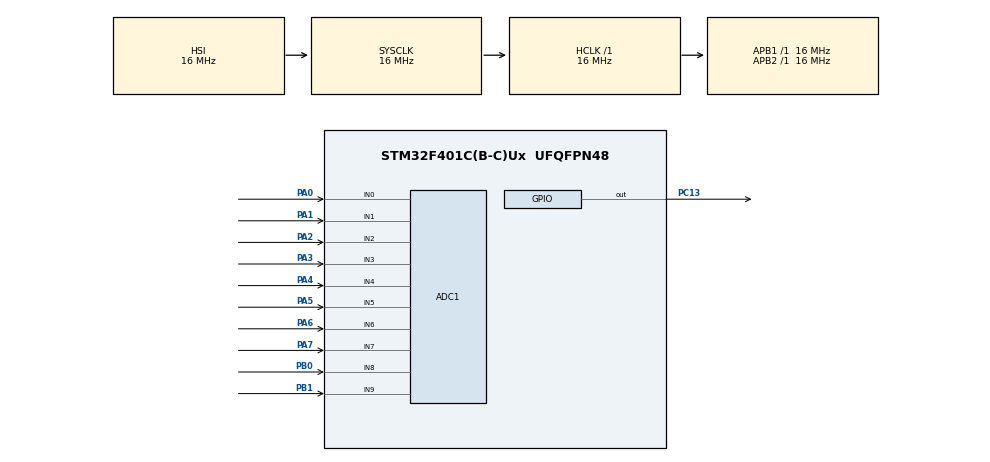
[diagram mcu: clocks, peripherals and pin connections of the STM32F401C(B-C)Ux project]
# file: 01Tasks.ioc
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ADC1.Channel-0\#ChannelRegularConversion=ADC_CHANNEL_0
ADC1.NbrOfConversionFlag=1
ADC1.Rank-0\#ChannelRegularConversion=1
ADC1.SamplingTime-0\#ChannelRegularConversion=ADC_SAMPLETIME_3CYCLES
ADC1.master=1
Mcu.Family=STM32F4
Mcu.Name=STM32F401C(B-C)Ux
Mcu.Package=UFQFPN48
NVIC.PriorityGroup=NVIC_PRIORITYGROUP_4
NVIC.TIM5_IRQn=true\:15\:0\:false\:false\:true\:false\:true\:true
NVIC.TimeBase=TIM5_IRQn
NVIC.TimeBaseIP=TIM5
PA0-WKUP.Signal=ADCx_IN0
PA1.Signal=ADCx_IN1
PA2.Signal=ADCx_IN2
PA3.Signal=ADCx_IN3
PA4.Signal=ADCx_IN4
PA5.Signal=ADCx_IN5
PA6.Signal=ADCx_IN6
PA7.Signal=ADCx_IN7
PB0.Signal=ADCx_IN8
PB1.Signal=ADCx_IN9
PC13-ANTI_TAMP.Signal=GPIO_Output
ProjectManager.HeapSize=0x100
ProjectManager.StackSize=0x200
ProjectManager.TargetToolchain=STM32CubeIDE
RCC.AHBFreq_Value=16000000
RCC.APB1Freq_Value=16000000
RCC.APB1TimFreq_Value=16000000
RCC.APB2Freq_Value=16000000
RCC.APB2TimFreq_Value=16000000
RCC.CortexFreq_Value=16000000
RCC.HCLKFreq_Value=16000000
RCC.HSE_VALUE=25000000
RCC.HSI_VALUE=16000000
RCC.LSE_VALUE=32768
RCC.SYSCLKFreq_VALUE=16000000
RCC.VCOOutputFreq_Value=192000000
SH.ADCx_IN0.0=ADC1_IN0,IN0
SH.ADCx_IN1.0=ADC1_IN1,IN1
SH.ADCx_IN2.0=ADC1_IN2,IN2
SH.ADCx_IN3.0=ADC1_IN3,IN3
SH.ADCx_IN4.0=ADC1_IN4,IN4
SH.ADCx_IN5.0=ADC1_IN5,IN5
SH.ADCx_IN6.0=ADC1_IN6,IN6
SH.ADCx_IN7.0=ADC1_IN7,IN7
SH.ADCx_IN8.0=ADC1_IN8,IN8
SH.ADCx_IN9.0=ADC1_IN9,IN9
VP_SYS_VS_tim5.Mode=TIM5
board=custom

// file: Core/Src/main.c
/* USER CODE BEGIN Header */
/**
  ******************************************************************************
  * @file           : main.c
  * @brief          : Main program body
  ******************************************************************************
  * @attention
  *
  * Copyright (c) 2024 STMicroelectronics.
  * All rights reserved.
  *
  * This software is licensed under terms that can be found in the LICENSE file
  * in the root directory of this software component.
  * If no LICENSE file comes with this software, it is provided AS-IS.
  *
  ******************************************************************************
  */
/* USER CODE END Header */
#include "main.h"

/* USER CODE BEGIN Includes */
#include "stdio.h"
#include "FreeRTOS.h"
#include "task.h"
#include "stm32f4xx.h"
#include "stm32f4xx_hal.h"
#include "stm32f4xx_hal_adc.h"
#include "stm32f4xx_hal_conf.h"
/* USER CODE END Includes */

/* USER CODE BEGIN PD */
#define TASK_STACK_SIZE 128  // Reduced stack size for tasks
#define TIMER_PERIOD pdMS_TO_TICKS(500)  // 500ms timer period
/* USER CODE END PD */

/* USER CODE BEGIN PV */
ADC_HandleTypeDef hadc1;
/* USER CODE END PV */

void SystemClock_Config(void);
static void MX_GPIO_Init(void);
static void MX_ADC1_Init(void);
/* USER CODE BEGIN PFP */
static void potentiometer_task(void* parameters);
/* USER CODE END PFP */

int main(void)
{
    /* USER CODE BEGIN 1 */
    HAL_Init();
    SystemClock_Config();
    MX_GPIO_Init();
    MX_ADC1_Init();

    /* Create the potentiometer task */
    xTaskCreate(potentiometer_task, "PotTask", TASK_STACK_SIZE, NULL, 1, NULL);

    /* Start scheduler */
    vTaskStartScheduler();

    while (1)
    {
    }
    /* USER CODE END 3 */
}

void SystemClock_Config(void)
{
    RCC_OscInitTypeDef RCC_OscInitStruct = {0};
    RCC_ClkInitTypeDef RCC_ClkInitStruct = {0};

    /** Configure the main internal regulator output voltage
    */
    __HAL_RCC_PWR_CLK_ENABLE();
    __HAL_PWR_VOLTAGESCALING_CONFIG(PWR_REGULATOR_VOLTAGE_SCALE2);

    /** Initializes the RCC Oscillators according to the specified parameters
    * in the RCC_OscInitTypeDef structure.
    */
    RCC_OscInitStruct.OscillatorType = RCC_OSCILLATORTYPE_HSI;
    RCC_OscInitStruct.HSIState = RCC_HSI_ON;
    RCC_OscInitStruct.HSICalibrationValue = RCC_HSICALIBRATION_DEFAULT;
    RCC_OscInitStruct.PLL.PLLState = RCC_PLL_NONE;
    if (HAL_RCC_OscConfig(&RCC_OscInitStruct) != HAL_OK)
    {
        Error_Handler();
    }
    /** Initializes the CPU, AHB and APB buses clocks
    */
    RCC_ClkInitStruct.ClockType = RCC_CLOCKTYPE_HCLK|RCC_CLOCKTYPE_SYSCLK
                                |RCC_CLOCKTYPE_PCLK1|RCC_CLOCKTYPE_PCLK2;
    RCC_ClkInitStruct.SYSCLKSource = RCC_SYSCLKSOURCE_HSI;
    RCC_ClkInitStruct.AHBCLKDivider = RCC_SYSCLK_DIV1;
    RCC_ClkInitStruct.APB1CLKDivider = RCC_HCLK_DIV1;
    RCC_ClkInitStruct.APB2CLKDivider = RCC_HCLK_DIV1;

    if (HAL_RCC_ClockConfig(&RCC_ClkInitStruct, FLASH_LATENCY_0) != HAL_OK)
    {
        Error_Handler();
    }
}

static void MX_GPIO_Init(void)
{
    GPIO_InitTypeDef GPIO_InitStruct = {0};

    /* GPIO Ports Clock Enable */
    __HAL_RCC_GPIOC_CLK_ENABLE();
    __HAL_RCC_GPIOA_CLK_ENABLE();

    /* Configure GPIO pin Output Level */
    HAL_GPIO_WritePin(GPIOC, GPIO_PIN_13, GPIO_PIN_RESET);

    /* Configure GPIO pin : PC13 (On-board LED) */
    GPIO_InitStruct.Pin = GPIO_PIN_13;
    GPIO_InitStruct.Mode = GPIO_MODE_OUTPUT_PP;
    GPIO_InitStruct.Pull = GPIO_NOPULL;
    GPIO_InitStruct.Speed = GPIO_SPEED_FREQ_LOW;
    HAL_GPIO_Init(GPIOC, &GPIO_InitStruct);

    /* Configure GPIO pin : PA0 (A0 - Potentiometer) */
    GPIO_InitStruct.Pin = GPIO_PIN_0;
    GPIO_InitStruct.Mode = GPIO_MODE_ANALOG;
    GPIO_InitStruct.Pull = GPIO_NOPULL;
    HAL_GPIO_Init(GPIOA, &GPIO_InitStruct);
}

/* USER CODE BEGIN 4 */

static void MX_ADC1_Init(void)
{
    ADC_ChannelConfTypeDef sConfig = {0};

    /* Enable ADC1 clock */
    __HAL_RCC_ADC1_CLK_ENABLE();

    /* Configure ADC1 peripheral */
    hadc1.Instance = ADC1;
    hadc1.Init.ClockPrescaler = ADC_CLOCK_SYNC_PCLK_DIV4;
    hadc1.Init.Resolution = ADC_RESOLUTION_12B;
    hadc1.Init.DataAlign = ADC_DATAALIGN_RIGHT;
    hadc1.Init.ScanConvMode = DISABLE;  // Disable scan conversion mode
    hadc1.Init.EOCSelection = ADC_EOC_SINGLE_CONV;
    hadc1.Init.ContinuousConvMode = DISABLE;
    hadc1.Init.DiscontinuousConvMode = DISABLE;
    hadc1.Init.NbrOfConversion = 1;
    hadc1.Init.ExternalTrigConv = ADC_SOFTWARE_START;
    hadc1.Init.ExternalTrigConvEdge = ADC_EXTERNALTRIGCONVEDGE_NONE;
    hadc1.Init.DMAContinuousRequests = DISABLE;

    /* Initialize ADC */
    if (HAL_ADC_Init(&hadc1) != HAL_OK)
    {
        Error_Handler();
    }

    /* Configure ADC channel */
    sConfig.Channel = ADC_CHANNEL_0;  // Adjust the channel if needed
    sConfig.Rank = 1;  // Use an integer value if constant is not available
    sConfig.SamplingTime = ADC_SAMPLETIME_3CYCLES;
    sConfig.Offset = 0;

    if (HAL_ADC_ConfigChannel(&hadc1, &sConfig) != HAL_OK)
    {
        Error_Handler();
    }
}

static void potentiometer_task(void* parameters)
{
    uint32_t adcValue;
    uint32_t ledThreshold = 2048; // Midpoint value for 12-bit ADC

    while (1)
    {
        // Start ADC Conversion
        HAL_ADC_Start(&hadc1);
        // Poll for end of conversion
        HAL_ADC_PollForConversion(&hadc1, HAL_MAX_DELAY);
        // Get the ADC value
        adcValue = HAL_ADC_GetValue(&hadc1);

        // Turn on LED if ADC value is above the threshold
        if (adcValue > ledThreshold)
        {
            HAL_GPIO_WritePin(GPIOC, GPIO_PIN_13, GPIO_PIN_SET); // Turn on LED
        }
        // Turn off LED if ADC value is below or equal to the threshold
        else
        {
            HAL_GPIO_WritePin(GPIOC, GPIO_PIN_13, GPIO_PIN_RESET); // Turn off LED
        }

        // Delay for a while
        vTaskDelay(pdMS_TO_TICKS(100));
    }
}
void Error_Handler(void)
{
    __disable_irq();
    while (1)
    {
    }
}
